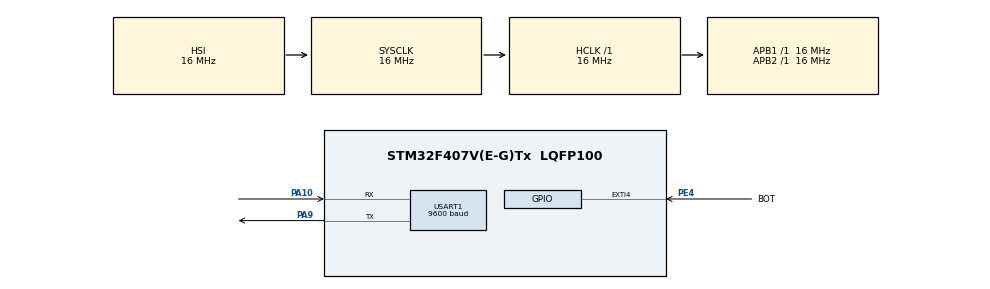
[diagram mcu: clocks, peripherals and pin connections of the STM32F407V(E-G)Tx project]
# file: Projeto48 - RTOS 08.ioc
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FREERTOS.Events01=myEvent01,Dynamic,NULL
FREERTOS.Tasks01=Tarefa1,24,128,Tarefa1_fun,Default,NULL,Dynamic,NULL,NULL;Tarefa2,24,128,Tarefa2_fun,Default,NULL,Dynamic,NULL,NULL
FREERTOS.configUSE_NEWLIB_REENTRANT=1
Mcu.Family=STM32F4
Mcu.Name=STM32F407V(E-G)Tx
Mcu.Package=LQFP100
NVIC.EXTI4_IRQn=true\:5\:0\:false\:false\:true\:true\:true\:true\:true
NVIC.PriorityGroup=NVIC_PRIORITYGROUP_4
NVIC.TIM1_UP_TIM10_IRQn=true\:15\:0\:false\:false\:true\:false\:false\:true\:true
NVIC.TimeBase=TIM1_UP_TIM10_IRQn
NVIC.TimeBaseIP=TIM1
PA10.Mode=Asynchronous
PA10.Signal=USART1_RX
PA9.Mode=Asynchronous
PA9.Signal=USART1_TX
PE4.GPIO_Label=BOT
PE4.Signal=GPXTI4
ProjectManager.HeapSize=0x200
ProjectManager.StackSize=0x400
ProjectManager.TargetToolchain=STM32CubeIDE
RCC.AHBFreq_Value=16000000
RCC.APB1Freq_Value=16000000
RCC.APB2Freq_Value=16000000
RCC.CortexFreq_Value=16000000
RCC.HSE_VALUE=25000000
RCC.HSI_VALUE=16000000
RCC.LSE_VALUE=32768
RCC.SYSCLKFreq_VALUE=16000000
RCC.VCOOutputFreq_Value=192000000
USART1.BaudRate=9600
USART1.Mode=MODE_TX
USART1.VirtualMode=VM_ASYNC
VP_FREERTOS_VS_CMSIS_V2.Mode=CMSIS_V2
VP_SYS_VS_tim1.Mode=TIM1
board=custom

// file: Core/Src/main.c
/* USER CODE BEGIN Header */
/**
  ******************************************************************************
  * @file           : main.c
  * @brief          : Main program body
  ******************************************************************************
  * @attention
  *
  * Copyright (c) 2023 STMicroelectronics.
  * All rights reserved.
  *
  * This software is licensed under terms that can be found in the LICENSE file
  * in the root directory of this software component.
  * If no LICENSE file comes with this software, it is provided AS-IS.
  *
  ******************************************************************************
  */
/* USER CODE END Header */
#include "main.h"
#include "cmsis_os.h"

/* USER CODE BEGIN Includes */

#include "string.h"

/* USER CODE END Includes */

 UART_HandleTypeDef huart1;

/* Definitions for Tarefa1 */
osThreadId_t Tarefa1Handle;
const osThreadAttr_t Tarefa1_attributes = {
  .name = "Tarefa1",
  .stack_size = 128 * 4,
  .priority = (osPriority_t) osPriorityNormal,
};
/* Definitions for Tarefa2 */
osThreadId_t Tarefa2Handle;
const osThreadAttr_t Tarefa2_attributes = {
  .name = "Tarefa2",
  .stack_size = 128 * 4,
  .priority = (osPriority_t) osPriorityNormal,
};
/* Definitions for myEvent01 */
osEventFlagsId_t myEvent01Handle;
const osEventFlagsAttr_t myEvent01_attributes = {
  .name = "myEvent01"
};

void SystemClock_Config(void);
static void MX_GPIO_Init(void);
static void MX_USART1_UART_Init(void);
void Tarefa1_fun(void *argument);
void Tarefa2_fun(void *argument);

/* USER CODE BEGIN PFP */

void HAL_GPIO_EXTI_Callback(uint16_t GPIO_Pin);

/* USER CODE END PFP */

int main(void)
{

  /* MCU Configuration--------------------------------------------------------*/

  /* Reset of all peripherals, Initializes the Flash interface and the Systick. */
  HAL_Init();

  /* Configure the system clock */
  SystemClock_Config();

  /* Initialize all configured peripherals */
  MX_GPIO_Init();
  MX_USART1_UART_Init();

  /* Init scheduler */
  osKernelInitialize();

  /* Create the thread(s) */
  /* creation of Tarefa1 */
  Tarefa1Handle = osThreadNew(Tarefa1_fun, NULL, &Tarefa1_attributes);

  /* creation of Tarefa2 */
  Tarefa2Handle = osThreadNew(Tarefa2_fun, NULL, &Tarefa2_attributes);

  /* Create the event(s) */
  /* creation of myEvent01 */
  myEvent01Handle = osEventFlagsNew(&myEvent01_attributes);

  /* Start scheduler */
  osKernelStart();

  /* We should never get here as control is now taken by the scheduler */
  /* Infinite loop */
  while (1)
  {

  }
}

void SystemClock_Config(void)
{
  RCC_OscInitTypeDef RCC_OscInitStruct = {0};
  RCC_ClkInitTypeDef RCC_ClkInitStruct = {0};

  /** Configure the main internal regulator output voltage
  */
  __HAL_RCC_PWR_CLK_ENABLE();
  __HAL_PWR_VOLTAGESCALING_CONFIG(PWR_REGULATOR_VOLTAGE_SCALE1);

  /** Initializes the RCC Oscillators according to the specified parameters
  * in the RCC_OscInitTypeDef structure.
  */
  RCC_OscInitStruct.OscillatorType = RCC_OSCILLATORTYPE_HSI;
  RCC_OscInitStruct.HSIState = RCC_HSI_ON;
  RCC_OscInitStruct.HSICalibrationValue = RCC_HSICALIBRATION_DEFAULT;
  RCC_OscInitStruct.PLL.PLLState = RCC_PLL_NONE;
  if (HAL_RCC_OscConfig(&RCC_OscInitStruct) != HAL_OK)
  {
    Error_Handler();
  }

  /** Initializes the CPU, AHB and APB buses clocks
  */
  RCC_ClkInitStruct.ClockType = RCC_CLOCKTYPE_HCLK|RCC_CLOCKTYPE_SYSCLK
                              |RCC_CLOCKTYPE_PCLK1|RCC_CLOCKTYPE_PCLK2;
  RCC_ClkInitStruct.SYSCLKSource = RCC_SYSCLKSOURCE_HSI;
  RCC_ClkInitStruct.AHBCLKDivider = RCC_SYSCLK_DIV1;
  RCC_ClkInitStruct.APB1CLKDivider = RCC_HCLK_DIV1;
  RCC_ClkInitStruct.APB2CLKDivider = RCC_HCLK_DIV1;

  if (HAL_RCC_ClockConfig(&RCC_ClkInitStruct, FLASH_LATENCY_0) != HAL_OK)
  {
    Error_Handler();
  }
}

static void MX_USART1_UART_Init(void)
{

  huart1.Instance = USART1;
  huart1.Init.BaudRate = 9600;
  huart1.Init.WordLength = UART_WORDLENGTH_8B;
  huart1.Init.StopBits = UART_STOPBITS_1;
  huart1.Init.Parity = UART_PARITY_NONE;
  huart1.Init.Mode = UART_MODE_TX;
  huart1.Init.HwFlowCtl = UART_HWCONTROL_NONE;
  huart1.Init.OverSampling = UART_OVERSAMPLING_16;
  if (HAL_UART_Init(&huart1) != HAL_OK)
  {
    Error_Handler();
  }

}

static void MX_GPIO_Init(void)
{
  GPIO_InitTypeDef GPIO_InitStruct = {0};

  /* GPIO Ports Clock Enable */
  __HAL_RCC_GPIOE_CLK_ENABLE();
  __HAL_RCC_GPIOA_CLK_ENABLE();

  /*Configure GPIO pin : BOT_Pin */
  GPIO_InitStruct.Pin = BOT_Pin;
  GPIO_InitStruct.Mode = GPIO_MODE_IT_RISING;
  GPIO_InitStruct.Pull = GPIO_NOPULL;
  HAL_GPIO_Init(BOT_GPIO_Port, &GPIO_InitStruct);

  /* EXTI interrupt init*/
  HAL_NVIC_SetPriority(EXTI4_IRQn, 5, 0);
  HAL_NVIC_EnableIRQ(EXTI4_IRQn);

}

/* USER CODE BEGIN 4 */

void HAL_GPIO_EXTI_Callback(uint16_t GPIO_Pin)
{
	if(GPIO_Pin == BOT_Pin)
	{
		osEventFlagsSet(myEvent01Handle, 0x20);
	}
}

/* USER CODE END 4 */

void Tarefa1_fun(void *argument)
{
  /* USER CODE BEGIN 5 */
  /* Infinite loop */
  for(;;)
  {
	  HAL_UART_Transmit(&huart1, (uint8_t *) "T1\n", strlen("T1\n"), 100);
	  osEventFlagsSet(myEvent01Handle, 0x10);
	  osDelay(1000);
  }
  /* USER CODE END 5 */
}

void Tarefa2_fun(void *argument)
{
  /* USER CODE BEGIN Tarefa2_fun */
  /* Infinite loop */
  for(;;)
  {
	  osEventFlagsWait(myEvent01Handle, 0x30, osFlagsWaitAll, osWaitForever);
	  HAL_UART_Transmit(&huart1, (uint8_t *) "T2\n", strlen("T2\n"), 100);
  }
  /* USER CODE END Tarefa2_fun */
}

void HAL_TIM_PeriodElapsedCallback(TIM_HandleTypeDef *htim)
{
  if (htim->Instance == TIM1) {
    HAL_IncTick();
  }
}

void Error_Handler(void)
{
  __disable_irq();
  while (1)
  {
  }
}
